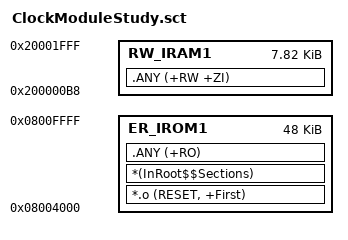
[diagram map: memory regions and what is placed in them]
; *************************************************************
; *** Scatter-Loading Description File generated by uVision ***
; *************************************************************

LR_IROM1 0x08004000 0x0000C000  {    ; load region size_region
  ER_IROM1 0x08004000 0x0000C000  {  ; load address = execution address
   *.o (RESET, +First)
   *(InRoot$$Sections)
   .ANY (+RO)
  }
  RW_IRAM1 0x200000B8 0x00001F48  {  ; RW data
   .ANY (+RW +ZI)
  }
}

